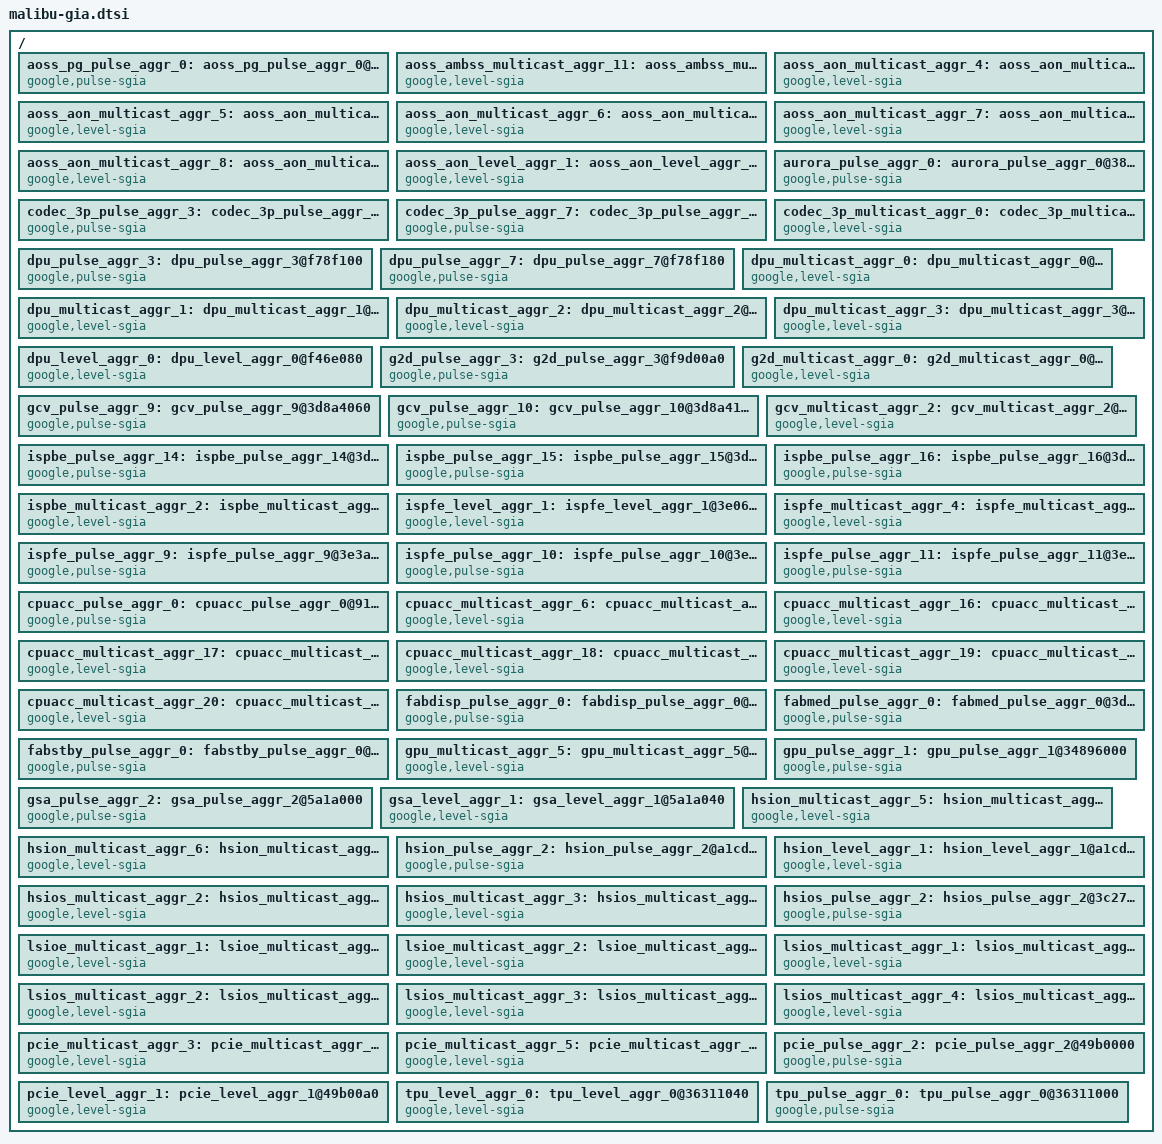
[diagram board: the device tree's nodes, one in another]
// SPDX-License-Identifier: GPL-2.0-only OR BSD-3-Clause
#include <dt-bindings/interrupt-controller/mbu-gic.h>
#include <dt-bindings/interrupt-controller/irq-gia-google-mbu.h>

/***** THIS FILE GENERATED USING gen-gia-device-tree.py *****/

/ {
	/* This node looks different because it is an N-N aggregator for aoss_pg_pulse_aggr_[0:6] */
	aoss_pg_pulse_aggr_0: aoss_pg_pulse_aggr_0@d856000 {
		compatible = "google,pulse-sgia";
		interrupt-controller;
		interrupt-parent = <&aoss_aon_multicast_aggr_8>;
		#interrupt-cells = <1>;
		reg = <0x0 0xd856000 0x0 0x20>;
		interrupts =
			<AOSS_GIA_MULTICAST_AGGR_8_AUX_PARTITION_INTR_PULSE_AGGR_INTR_0>,
			<AOSS_GIA_MULTICAST_AGGR_8_AUX_PARTITION_INTR_PULSE_AGGR_INTR_1>,
			<AOSS_GIA_MULTICAST_AGGR_8_AUX_PARTITION_INTR_PULSE_AGGR_INTR_2>,
			<AOSS_GIA_MULTICAST_AGGR_8_AUX_PARTITION_INTR_PULSE_AGGR_INTR_3>,
			<AOSS_GIA_MULTICAST_AGGR_8_AUX_PARTITION_INTR_PULSE_AGGR_INTR_4>,
			<AOSS_GIA_MULTICAST_AGGR_8_AUX_PARTITION_INTR_PULSE_AGGR_INTR_5>,
			<AOSS_GIA_MULTICAST_AGGR_8_AUX_PARTITION_INTR_PULSE_AGGR_INTR_6>;
	};

	aoss_ambss_multicast_aggr_11: aoss_ambss_multicast_aggr_11@d105000 {
		compatible = "google,level-sgia";
		interrupt-controller;
		#interrupt-cells = <1>;
		reg = <0x0 0xd105000 0x0 0x20>;
		interrupts = <GIC_SPI SSWRP_AOSS_AOSS_AP_INTR_NS_AOSSAMBSS_0 IRQ_TYPE_LEVEL_HIGH 0>;
	};

	aoss_aon_multicast_aggr_4: aoss_aon_multicast_aggr_4@e602020 {
		compatible = "google,level-sgia";
		interrupt-controller;
		interrupt-parent = <&aoss_aon_level_aggr_1>;
		#interrupt-cells = <1>;
		reg = <0x0 0xe602020 0x0 0x20>;
		interrupts = <AOSS_GIA_LEVEL_AGGR_1_AUX_AON_AON_PARTITION_AON_GIA_GIA_MULTICAST_AGGR_INTR_4>;
	};

	aoss_aon_multicast_aggr_5: aoss_aon_multicast_aggr_5@e602040 {
		compatible = "google,level-sgia";
		interrupt-controller;
		interrupt-parent = <&aoss_aon_level_aggr_1>;
		#interrupt-cells = <1>;
		reg = <0x0 0xe602040 0x0 0x20>;
		interrupts = <AOSS_GIA_LEVEL_AGGR_1_AUX_AON_AON_PARTITION_AON_GIA_GIA_MULTICAST_AGGR_INTR_5>;
	};

	aoss_aon_multicast_aggr_6: aoss_aon_multicast_aggr_6@e602060 {
		compatible = "google,level-sgia";
		interrupt-controller;
		interrupt-parent = <&aoss_aon_level_aggr_1>;
		#interrupt-cells = <1>;
		reg = <0x0 0xe602060 0x0 0x20>;
		interrupts = <AOSS_GIA_LEVEL_AGGR_1_AUX_AON_AON_PARTITION_AON_GIA_GIA_MULTICAST_AGGR_INTR_6>;
	};

	aoss_aon_multicast_aggr_7: aoss_aon_multicast_aggr_7@e602080 {
		compatible = "google,level-sgia";
		interrupt-controller;
		interrupt-parent = <&aoss_aon_level_aggr_1>;
		#interrupt-cells = <1>;
		reg = <0x0 0xe602080 0x0 0x20>;
		interrupts = <AOSS_GIA_LEVEL_AGGR_1_AUX_AON_AON_PARTITION_AON_GIA_GIA_MULTICAST_AGGR_INTR_7>;
	};

	aoss_aon_multicast_aggr_8: aoss_aon_multicast_aggr_8@e6020a0 {
		compatible = "google,level-sgia";
		interrupt-controller;
		interrupt-parent = <&aoss_aon_level_aggr_1>;
		#interrupt-cells = <1>;
		reg = <0x0 0xe6020a0 0x0 0x20>;
		interrupts = <AOSS_GIA_LEVEL_AGGR_1_AUX_AON_AON_PARTITION_AON_GIA_GIA_MULTICAST_AGGR_INTR_8>;
	};

	aoss_aon_level_aggr_1: aoss_aon_level_aggr_1@e6020c0 {
		compatible = "google,level-sgia";
		interrupt-controller;
		#interrupt-cells = <1>;
		reg = <0x0 0xe6020c0 0x0 0x20>;
		interrupts = <GIC_SPI SSWRP_AOSS_AOSS_GIA_OUT_AP_NS_0 IRQ_TYPE_LEVEL_HIGH 0>;
	};

	aurora_pulse_aggr_0: aurora_pulse_aggr_0@38061000 {
		compatible = "google,pulse-sgia";
		interrupt-controller;
		#interrupt-cells = <1>;
		reg = <0x0 0x38061000 0x0 0x20>;
		interrupts = <GIC_SPI SSWRP_AURORA_AURDSP_GIA_OUT_AP_NS_0 IRQ_TYPE_LEVEL_HIGH 0>;
		power-domains = <&sswrp_aurdsp_pd>;
	};

	codec_3p_pulse_aggr_3: codec_3p_pulse_aggr_3@3da700c0 {
		compatible = "google,pulse-sgia";
		interrupt-controller;
		interrupt-parent = <&codec_3p_multicast_aggr_0>;
		#interrupt-cells = <1>;
		reg = <0x0 0x3da700c0 0x0 0x20>;
		interrupts = <CODEC_3P_GIA_MULTICAST_AGGR_0_AUX_AON_DUMMY_GIA_LEAF_WRAPPER_PULSE_AGGR_INTR_3>;
		power-domains = <&sswrp_codec_3p_pd>;
	};

	codec_3p_pulse_aggr_7: codec_3p_pulse_aggr_7@3da700e0 {
		compatible = "google,pulse-sgia";
		interrupt-controller;
		interrupt-parent = <&codec_3p_multicast_aggr_0>;
		#interrupt-cells = <1>;
		reg = <0x0 0x3da700e0 0x0 0x20>;
		interrupts = <CODEC_3P_GIA_MULTICAST_AGGR_0_AUX_AON_DUMMY_GIA_LEAF_WRAPPER_PULSE_AGGR_INTR_7>;
		power-domains = <&sswrp_codec_3p_pd>;
	};

	codec_3p_multicast_aggr_0: codec_3p_multicast_aggr_0@3da6a000 {
		compatible = "google,level-sgia";
		interrupt-controller;
		#interrupt-cells = <1>;
		reg = <0x0 0x3da6a000 0x0 0x20>;
		interrupts = <GIC_SPI SSWRP_CODEC_3P_CODEC3P_GIA_OUT_AP_NS IRQ_TYPE_LEVEL_HIGH 0>;
		power-domains = <&sswrp_codec_3p_pd>;
	};

	dpu_pulse_aggr_3: dpu_pulse_aggr_3@f78f100 {
		compatible = "google,pulse-sgia";
		interrupt-controller;
		interrupt-parent = <&dpu_multicast_aggr_2>;
		#interrupt-cells = <1>;
		reg = <0x0 0xf78f100 0x0 0x20>;
		interrupts = <DPU_GIA_MULTICAST_AGGR_2_AUX_CORE_IRQ_DUMMY_GIA_LEAF_WRAPPER_PULSE_AGGR_INTR_3>;
		power-domains = <&sswrp_dpu_pd>;
	};

	dpu_pulse_aggr_7: dpu_pulse_aggr_7@f78f180 {
		compatible = "google,pulse-sgia";
		interrupt-controller;
		interrupt-parent = <&dpu_multicast_aggr_3>;
		#interrupt-cells = <1>;
		reg = <0x0 0xf78f180 0x0 0x20>;
		interrupts = <DPU_GIA_MULTICAST_AGGR_3_AUX_CORE_IRQ_DUMMY_GIA_LEAF_WRAPPER_PULSE_AGGR_INTR_7>;
		power-domains = <&sswrp_dpu_pd>;
	};

	dpu_multicast_aggr_0: dpu_multicast_aggr_0@f46e000 {
		compatible = "google,level-sgia";
		interrupt-controller;
		interrupt-parent = <&dpu_level_aggr_0>;
		#interrupt-cells = <1>;
		reg = <0x0 0xf46e000 0x0 0x20>;
		interrupts = <DPU_GIA_LEVEL_AGGR_0_AUX_AON_GIA_GIA_GIA_MULTICAST_AGGR_INTR_0>;
		power-domains = <&sswrp_dpu_pd>;
	};

	dpu_multicast_aggr_1: dpu_multicast_aggr_1@f46e020 {
		compatible = "google,level-sgia";
		interrupt-controller;
		interrupt-parent = <&dpu_level_aggr_0>;
		#interrupt-cells = <1>;
		reg = <0x0 0xf46e020 0x0 0x20>;
		interrupts = <DPU_GIA_LEVEL_AGGR_0_AUX_AON_GIA_GIA_GIA_MULTICAST_AGGR_INTR_1>;
		power-domains = <&sswrp_dpu_pd>;
	};

	dpu_multicast_aggr_2: dpu_multicast_aggr_2@f46e040 {
		compatible = "google,level-sgia";
		interrupt-controller;
		interrupt-parent = <&dpu_level_aggr_0>;
		#interrupt-cells = <1>;
		reg = <0x0 0xf46e040 0x0 0x20>;
		interrupts = <DPU_GIA_LEVEL_AGGR_0_AUX_AON_GIA_GIA_GIA_MULTICAST_AGGR_INTR_2>;
		power-domains = <&sswrp_dpu_pd>;
	};

	dpu_multicast_aggr_3: dpu_multicast_aggr_3@f46e060 {
		compatible = "google,level-sgia";
		interrupt-controller;
		interrupt-parent = <&dpu_level_aggr_0>;
		#interrupt-cells = <1>;
		reg = <0x0 0xf46e060 0x0 0x20>;
		interrupts = <DPU_GIA_LEVEL_AGGR_0_AUX_AON_GIA_GIA_GIA_MULTICAST_AGGR_INTR_3>;
		power-domains = <&sswrp_dpu_pd>;
	};

	dpu_level_aggr_0: dpu_level_aggr_0@f46e080 {
		compatible = "google,level-sgia";
		interrupt-controller;
		#interrupt-cells = <1>;
		reg = <0x0 0xf46e080 0x0 0x20>;
		interrupts = <GIC_SPI SSWRP_DPU_DPU_GIA_OUT_AP_NS IRQ_TYPE_LEVEL_HIGH 0>;
		power-domains = <&sswrp_dpu_pd>;
	};

	g2d_pulse_aggr_3: g2d_pulse_aggr_3@f9d00a0 {
		compatible = "google,pulse-sgia";
		interrupt-controller;
		interrupt-parent = <&g2d_multicast_aggr_0>;
		#interrupt-cells = <1>;
		reg = <0x0 0xf9d00a0 0x0 0x20>;
		interrupts = <G2D_GIA_MULTICAST_AGGR_0_AUX_CORE_IRQ_DUMMY_GIA_LEAF_WRAPPER_PULSE_AGGR_INTR_3>;
		power-domains = <&sswrp_g2d_pd>;
	};

	g2d_multicast_aggr_0: g2d_multicast_aggr_0@f822000 {
		compatible = "google,level-sgia";
		interrupt-controller;
		#interrupt-cells = <1>;
		reg = <0x0 0xf822000 0x0 0x20>;
		interrupts = <GIC_SPI SSWRP_G2D_G2D_GIA_OUT_AP_NS IRQ_TYPE_LEVEL_HIGH 0>;
		power-domains = <&sswrp_g2d_pd>;
	};

	gcv_pulse_aggr_9: gcv_pulse_aggr_9@3d8a4060 {
		compatible = "google,pulse-sgia";
		interrupt-controller;
		interrupt-parent = <&gcv_multicast_aggr_2>;
		#interrupt-cells = <1>;
		reg = <0x0 0x3d8a4060 0x0 0x20>;
		interrupts = <GCV_GIA_MULTICAST_AGGR_2_AUX_PD_AUX_QCHWRAP_DUMMY_GIA_LEAF_WRAPPER_PULSE_AGGR_INTR_9>;
		power-domains = <&sswrp_gcv_pd>;
	};

	gcv_pulse_aggr_10: gcv_pulse_aggr_10@3d8a4160 {
		compatible = "google,pulse-sgia";
		interrupt-controller;
		interrupt-parent = <&gcv_multicast_aggr_2>;
		#interrupt-cells = <1>;
		reg = <0x0 0x3d8a4160 0x0 0x20>;
		interrupts = <GCV_GIA_MULTICAST_AGGR_2_AUX_PD_AUX_QCHWRAP_DUMMY_GIA_LEAF_WRAPPER_PULSE_AGGR_INTR_10>;
		power-domains = <&sswrp_gcv_pd>;
	};

	gcv_multicast_aggr_2: gcv_multicast_aggr_2@3d812000 {
		compatible = "google,level-sgia";
		interrupt-controller;
		#interrupt-cells = <1>;
		reg = <0x0 0x3d812000 0x0 0x20>;
		interrupts = <GIC_SPI SSWRP_GCV_GCV_GIA_OUT_AP_NS IRQ_TYPE_LEVEL_HIGH 0>;
		power-domains = <&sswrp_gcv_pd>;
	};

	ispbe_pulse_aggr_14: ispbe_pulse_aggr_14@3d637060 {
		compatible = "google,pulse-sgia";
		interrupt-controller;
		interrupt-parent = <&ispbe_multicast_aggr_2>;
		#interrupt-cells = <1>;
		reg = <0x0 0x3d637060 0x0 0x20>;
		interrupts = <ISPBE_GIA_MULTICAST_AGGR_2_AUX_PD_AUX_QCHWRAP_DUMMY_GIA_LEAF_WRAPPER_PULSE_AGGR_INTR_14>;
		power-domains = <&sswrp_ispbe_pd>;
	};

	ispbe_pulse_aggr_15: ispbe_pulse_aggr_15@3d637160 {
		compatible = "google,pulse-sgia";
		interrupt-controller;
		interrupt-parent = <&ispbe_multicast_aggr_2>;
		#interrupt-cells = <1>;
		reg = <0x0 0x3d637160 0x0 0x20>;
		interrupts = <ISPBE_GIA_MULTICAST_AGGR_2_AUX_PD_AUX_QCHWRAP_DUMMY_GIA_LEAF_WRAPPER_PULSE_AGGR_INTR_15>;
		power-domains = <&sswrp_ispbe_pd>;
	};

	ispbe_pulse_aggr_16: ispbe_pulse_aggr_16@3d637260 {
		compatible = "google,pulse-sgia";
		interrupt-controller;
		interrupt-parent = <&ispbe_multicast_aggr_2>;
		#interrupt-cells = <1>;
		reg = <0x0 0x3d637260 0x0 0x20>;
		interrupts = <ISPBE_GIA_MULTICAST_AGGR_2_AUX_PD_AUX_QCHWRAP_DUMMY_GIA_LEAF_WRAPPER_PULSE_AGGR_INTR_16>;
		power-domains = <&sswrp_ispbe_pd>;
	};

	ispbe_multicast_aggr_2: ispbe_multicast_aggr_2@3d412000 {
		compatible = "google,level-sgia";
		interrupt-controller;
		#interrupt-cells = <1>;
		reg = <0x0 0x3d412000 0x0 0x20>;
		interrupts = <GIC_SPI SSWRP_ISPBE_ISPBE_GIA_OUT_AP_NS IRQ_TYPE_LEVEL_HIGH 0>;
		power-domains = <&sswrp_ispbe_pd>;
	};

	ispfe_level_aggr_1: ispfe_level_aggr_1@3e063040 {
		compatible = "google,level-sgia";
		interrupt-controller;
		#interrupt-cells = <1>;
		reg = <0x0 0x3e063040 0x0 0x20>;
		interrupts = <GIC_SPI SSWRP_ISPFE_ISPFE_GIA_OUT_AP_NS IRQ_TYPE_LEVEL_HIGH 0>;
		power-domains = <&sswrp_ispfe_pd>;
	};

	ispfe_multicast_aggr_4: ispfe_multicast_aggr_4@3e063000 {
		compatible = "google,level-sgia";
		interrupt-controller;
		interrupt-parent = <&ispfe_level_aggr_1>;
		#interrupt-cells = <1>;
		reg = <0x0 0x3e063000 0x0 0x20>;
		interrupts = <ISPFE_GIA_LEVEL_AGGR_1_AUX_AON_AON_GIA_MULTICAST_AGGR_INTR_4>;
		power-domains = <&sswrp_ispfe_pd>;
	};

	ispfe_pulse_aggr_9: ispfe_pulse_aggr_9@3e3a0120 {
		compatible = "google,pulse-sgia";
		interrupt-controller;
		interrupt-parent = <&ispfe_multicast_aggr_4>;
		#interrupt-cells = <1>;
		reg = <0x0 0x3e3a0120 0x0 0x20>;
		interrupts = <ISPFE_GIA_MULTICAST_AGGR_4_AUX_DUMMY_GIA_LEAF_WRAPPER_PULSE_AGGR_INTR_9>;
		power-domains = <&sswrp_ispfe_pd>;
	};

	ispfe_pulse_aggr_10: ispfe_pulse_aggr_10@3e3a0140 {
		compatible = "google,pulse-sgia";
		interrupt-controller;
		interrupt-parent = <&ispfe_multicast_aggr_4>;
		#interrupt-cells = <1>;
		reg = <0x0 0x3e3a0140 0x0 0x20>;
		interrupts = <ISPFE_GIA_MULTICAST_AGGR_4_AUX_DUMMY_GIA_LEAF_WRAPPER_PULSE_AGGR_INTR_10>;
		power-domains = <&sswrp_ispfe_pd>;
	};

	ispfe_pulse_aggr_11: ispfe_pulse_aggr_11@3e3a0160 {
		compatible = "google,pulse-sgia";
		interrupt-controller;
		interrupt-parent = <&ispfe_multicast_aggr_4>;
		#interrupt-cells = <1>;
		reg = <0x0 0x3e3a0160 0x0 0x20>;
		interrupts = <ISPFE_GIA_MULTICAST_AGGR_4_AUX_DUMMY_GIA_LEAF_WRAPPER_PULSE_AGGR_INTR_11>;
		power-domains = <&sswrp_ispfe_pd>;
	};

	cpuacc_pulse_aggr_0: cpuacc_pulse_aggr_0@91c2000 {
		compatible = "google,pulse-sgia";
		interrupt-controller;
		#interrupt-cells = <1>;
		reg = <0x0 0x91c2000 0x0 0x20>;
		interrupts = <GIC_SPI SSWRP_CPUACC_CPUACC_GIA_OUT_AP_NS_0 IRQ_TYPE_LEVEL_HIGH 0>;
	};

	cpuacc_multicast_aggr_6: cpuacc_multicast_aggr_6@91c2020 {
		compatible = "google,level-sgia";
		interrupt-controller;
		#interrupt-cells = <1>;
		reg = <0x0 0x91c2020 0x0 0x20>;
		interrupts = <GIC_SPI SSWRP_CPUACC_CPUACC_GIA_OUT_AP_NS_1 IRQ_TYPE_LEVEL_HIGH 0>;
	};

	cpuacc_multicast_aggr_16: cpuacc_multicast_aggr_16@91c6000 {
		compatible = "google,level-sgia";
		interrupt-controller;
		#interrupt-cells = <1>;
		reg = <0x0 0x91c6000 0x0 0x20>;
		interrupts = <GIC_SPI SSWRP_CPUACC_CPUACC_GIA_OUT_AP_0_0 IRQ_TYPE_LEVEL_HIGH 0>;
	};

	cpuacc_multicast_aggr_17: cpuacc_multicast_aggr_17@91c7000 {
		compatible = "google,level-sgia";
		interrupt-controller;
		#interrupt-cells = <1>;
		reg = <0x0 0x91c7000 0x0 0x20>;
		interrupts = <GIC_SPI SSWRP_CPUACC_CPUACC_GIA_OUT_AP_0_1 IRQ_TYPE_LEVEL_HIGH 0>;
	};

	cpuacc_multicast_aggr_18: cpuacc_multicast_aggr_18@91c8000 {
		compatible = "google,level-sgia";
		interrupt-controller;
		#interrupt-cells = <1>;
		reg = <0x0 0x91c8000 0x0 0x20>;
		interrupts = <GIC_SPI SSWRP_CPUACC_CPUACC_GIA_OUT_AP_0_2 IRQ_TYPE_LEVEL_HIGH 0>;
	};

	cpuacc_multicast_aggr_19: cpuacc_multicast_aggr_19@91c9000 {
		compatible = "google,level-sgia";
		interrupt-controller;
		#interrupt-cells = <1>;
		reg = <0x0 0x91c9000 0x0 0x20>;
		interrupts = <GIC_SPI SSWRP_CPUACC_CPUACC_GIA_OUT_AP_0_3 IRQ_TYPE_LEVEL_HIGH 0>;
	};

	cpuacc_multicast_aggr_20: cpuacc_multicast_aggr_20@91ca000 {
		compatible = "google,level-sgia";
		interrupt-controller;
		#interrupt-cells = <1>;
		reg = <0x0 0x91ca000 0x0 0x20>;
		interrupts = <GIC_SPI SSWRP_CPUACC_CPUACC_GIA_OUT_AP_0_4 IRQ_TYPE_LEVEL_HIGH 0>;
	};

	fabdisp_pulse_aggr_0: fabdisp_pulse_aggr_0@f371000 {
		compatible = "google,pulse-sgia";
		interrupt-controller;
		#interrupt-cells = <1>;
		reg = <0x0 0xf371000 0x0 0x20>;
		interrupts = <GIC_SPI SSWRP_FABDISP_FABDISP_GIA_OUT_AP_NS_0 IRQ_TYPE_LEVEL_HIGH 0>;
	};

	fabmed_pulse_aggr_0: fabmed_pulse_aggr_0@3d371000 {
		compatible = "google,pulse-sgia";
		interrupt-controller;
		#interrupt-cells = <1>;
		reg = <0x0 0x3d371000 0x0 0x20>;
		interrupts = <GIC_SPI SSWRP_FABMED_FABMED_GIA_OUT_AP_NS_0 IRQ_TYPE_LEVEL_HIGH 0>;
	};

	fabstby_pulse_aggr_0: fabstby_pulse_aggr_0@4371000 {
		compatible = "google,pulse-sgia";
		interrupt-controller;
		#interrupt-cells = <1>;
		reg = <0x0 0x4371000 0x0 0x20>;
		interrupts = <GIC_SPI SSWRP_FABSTBY_FABSTBY_GIA_OUT_AP_NS_0 IRQ_TYPE_LEVEL_HIGH 0>;
	};

	gpu_multicast_aggr_5: gpu_multicast_aggr_5@34896020 {
		compatible = "google,level-sgia";
		interrupt-controller;
		#interrupt-cells = <1>;
		reg = <0x0 0x34896020 0x0 0x20>;
		interrupts = <GIC_SPI SSWRP_GPU_GPU_GIA_OUT_AP_NS IRQ_TYPE_LEVEL_HIGH 0>;
		power-domains = <&sswrp_gpu_pd>;
	};

	gpu_pulse_aggr_1: gpu_pulse_aggr_1@34896000 {
		compatible = "google,pulse-sgia";
		interrupt-controller;
		interrupt-parent = <&gpu_multicast_aggr_5>;
		#interrupt-cells = <1>;
		reg = <0x0 0x34896000 0x0 0x20>;
		interrupts = <GPU_GIA_MULTICAST_AGGR_5_AUX_AON_AON_GIA_PULSE_AGGR_INTR_1>;
		power-domains = <&sswrp_gpu_pd>;
	};

	gsa_pulse_aggr_2: gsa_pulse_aggr_2@5a1a000 {
		compatible = "google,pulse-sgia";
		interrupt-controller;
		interrupt-parent = <&gsa_level_aggr_1>;
		#interrupt-cells = <1>;
		reg = <0x0 0x5a1a000 0x0 0x20>;
		interrupts = <GSA_GIA_LEVEL_AGGR_1_AUX_AON_AON_GIA_GIA_PULSE_AGGR_INTR_2>;
	};

	gsa_level_aggr_1: gsa_level_aggr_1@5a1a040 {
		compatible = "google,level-sgia";
		interrupt-controller;
		#interrupt-cells = <1>;
		reg = <0x0 0x5a1a040 0x0 0x20>;
		interrupts = <GIC_SPI SSWRP_GSA_GSA_GIA_OUT_AP_NS IRQ_TYPE_LEVEL_HIGH 0>;
	};

	hsion_multicast_aggr_5: hsion_multicast_aggr_5@a1cd060 {
		compatible = "google,level-sgia";
		interrupt-controller;
		#interrupt-cells = <1>;
		reg = <0x0 0xa1cd060 0x0 0x20>;
		interrupts = <GIC_SPI SSWRP_HSIO_N_HSION_GIA_OUT_AP_NS_1 IRQ_TYPE_LEVEL_HIGH 0>;
		power-domains = <&sswrp_hsio_n_pd>;
	};

	hsion_multicast_aggr_6: hsion_multicast_aggr_6@a1cd080 {
		compatible = "google,level-sgia";
		interrupt-controller;
		#interrupt-cells = <1>;
		reg = <0x0 0xa1cd080 0x0 0x20>;
		interrupts = <GIC_SPI SSWRP_HSIO_N_HSION_GIA_OUT_AP_NS_2 IRQ_TYPE_LEVEL_HIGH 0>;
		power-domains = <&sswrp_hsio_n_pd>;
	};

	hsion_pulse_aggr_2: hsion_pulse_aggr_2@a1cd000 {
		compatible = "google,pulse-sgia";
		interrupt-controller;
		interrupt-parent = <&hsion_level_aggr_1>;
		#interrupt-cells = <1>;
		reg = <0x0 0xa1cd000 0x0 0x20>;
		interrupts = <HSION_GIA_LEVEL_AGGR_1_HSIO_N_AUX_HSIO_N_HSIO_N_GIA_PULSE_AGGR_INTR_2>;
		power-domains = <&sswrp_hsio_n_pd>;
	};

	hsion_level_aggr_1: hsion_level_aggr_1@a1cd0a0 {
		compatible = "google,level-sgia";
		interrupt-controller;
		#interrupt-cells = <1>;
		reg = <0x0 0xa1cd0a0 0x0 0x20>;
		interrupts = <GIC_SPI SSWRP_HSIO_N_HSION_GIA_OUT_AP_NS_3 IRQ_TYPE_LEVEL_HIGH 0>;
		power-domains = <&sswrp_hsio_n_pd>;
	};

	hsios_multicast_aggr_2: hsios_multicast_aggr_2@3c272040 {
		compatible = "google,level-sgia";
		interrupt-controller;
		#interrupt-cells = <1>;
		reg = <0x0 0x3c272040 0x0 0x20>;
		interrupts = <GIC_SPI SSWRP_HSIO_S_HSIOS_GIA_OUT_AP_NS_2 IRQ_TYPE_LEVEL_HIGH 0>;
		power-domains = <&sswrp_hsio_s_pd>;
	};

	hsios_multicast_aggr_3: hsios_multicast_aggr_3@3c272060 {
		compatible = "google,level-sgia";
		interrupt-controller;
		#interrupt-cells = <1>;
		reg = <0x0 0x3c272060 0x0 0x20>;
		interrupts = <GIC_SPI SSWRP_HSIO_S_HSIOS_GIA_OUT_AP_NS_3 IRQ_TYPE_LEVEL_HIGH 0>;
		power-domains = <&sswrp_hsio_s_pd>;
	};

	hsios_pulse_aggr_2: hsios_pulse_aggr_2@3c272000 {
		compatible = "google,pulse-sgia";
		interrupt-controller;
		#interrupt-cells = <1>;
		reg = <0x0 0x3c272000 0x0 0x20>;
		interrupts = <GIC_SPI SSWRP_HSIO_S_HSIOS_GIA_OUT_AP_NS_0 IRQ_TYPE_LEVEL_HIGH 0>;
		power-domains = <&sswrp_hsio_s_pd>;
	};

	lsioe_multicast_aggr_1: lsioe_multicast_aggr_1@3a0d2020 {
		compatible = "google,level-sgia";
		interrupt-controller;
		#interrupt-cells = <1>;
		reg = <0x0 0x3a0d2020 0x0 0x20>;
		interrupts = <GIC_SPI SSWRP_LSIOE_LSIOE_GIA_OUT_AP_NS_1 IRQ_TYPE_LEVEL_HIGH 0>;
		power-domains = <&sswrp_lsio_e_pd>;
	};

	lsioe_multicast_aggr_2: lsioe_multicast_aggr_2@3a0d2040 {
		compatible = "google,level-sgia";
		interrupt-controller;
		#interrupt-cells = <1>;
		reg = <0x0 0x3a0d2040 0x0 0x20>;
		interrupts = <GIC_SPI SSWRP_LSIOE_LSIOE_GIA_OUT_AP_NS_2 IRQ_TYPE_LEVEL_HIGH 0>;
		power-domains = <&sswrp_lsio_e_pd>;
	};

	lsios_multicast_aggr_1: lsios_multicast_aggr_1@3bcd2020 {
		compatible = "google,level-sgia";
		interrupt-controller;
		#interrupt-cells = <1>;
		reg = <0x0 0x3bcd2020 0x0 0x20>;
		interrupts = <GIC_SPI SSWRP_LSIOS_LSIOS_GIA_OUT_AP_NS_1 IRQ_TYPE_LEVEL_HIGH 0>;
		power-domains = <&sswrp_lsio_s_pd>;
	};

	lsios_multicast_aggr_2: lsios_multicast_aggr_2@3bcd2040 {
		compatible = "google,level-sgia";
		interrupt-controller;
		#interrupt-cells = <1>;
		reg = <0x0 0x3bcd2040 0x0 0x20>;
		interrupts = <GIC_SPI SSWRP_LSIOS_LSIOS_GIA_OUT_AP_NS_2 IRQ_TYPE_LEVEL_HIGH 0>;
		power-domains = <&sswrp_lsio_s_pd>;
	};

	lsios_multicast_aggr_3: lsios_multicast_aggr_3@3bcd2060 {
		compatible = "google,level-sgia";
		interrupt-controller;
		#interrupt-cells = <1>;
		reg = <0x0 0x3bcd2060 0x0 0x20>;
		interrupts = <GIC_SPI SSWRP_LSIOS_LSIOS_GIA_OUT_AP_NS_3 IRQ_TYPE_LEVEL_HIGH 0>;
		power-domains = <&sswrp_lsio_s_pd>;
	};

	lsios_multicast_aggr_4: lsios_multicast_aggr_4@3bcd2080 {
		compatible = "google,level-sgia";
		interrupt-controller;
		#interrupt-cells = <1>;
		reg = <0x0 0x3bcd2080 0x0 0x20>;
		interrupts = <GIC_SPI SSWRP_LSIOS_LSIOS_GIA_OUT_AP_NS_4 IRQ_TYPE_LEVEL_HIGH 0>;
		power-domains = <&sswrp_lsio_s_pd>;
	};

	pcie_multicast_aggr_3: pcie_multicast_aggr_3@49b0040 {
		compatible = "google,level-sgia";
		interrupt-controller;
		interrupt-parent = <&pcie_level_aggr_1>;
		#interrupt-cells = <1>;
		reg = <0x0 0x49b0040 0x0 0x20>;
		interrupts = <PCIE_GIA_LEVEL_AGGR_1_AUX_GIA_MULTICAST_AGGR_INTR_3>;
		power-domains = <&sswrp_pcie_pd>;
	};

	pcie_multicast_aggr_5: pcie_multicast_aggr_5@49b0080 {
		compatible = "google,level-sgia";
		interrupt-controller;
		interrupt-parent = <&pcie_level_aggr_1>;
		#interrupt-cells = <1>;
		reg = <0x0 0x49b0080 0x0 0x20>;
		interrupts = <PCIE_GIA_LEVEL_AGGR_1_AUX_GIA_MULTICAST_AGGR_INTR_5>;
		power-domains = <&sswrp_pcie_pd>;
	};

	pcie_pulse_aggr_2: pcie_pulse_aggr_2@49b0000 {
		compatible = "google,pulse-sgia";
		interrupt-controller;
		interrupt-parent = <&pcie_level_aggr_1>;
		#interrupt-cells = <1>;
		reg = <0x0 0x49b0000 0x0 0x20>;
		interrupts = <PCIE_GIA_LEVEL_AGGR_1_AUX_GIA_PULSE_AGGR_INTR_2>;
		power-domains = <&sswrp_pcie_pd>;
	};

	pcie_level_aggr_1: pcie_level_aggr_1@49b00a0 {
		compatible = "google,level-sgia";
		interrupt-controller;
		#interrupt-cells = <1>;
		reg = <0x0 0x49b00a0 0x0 0x20>;
		interrupts = <GIC_SPI SSWRP_PCIE_PCIE_GIA_OUT_AP_NS IRQ_TYPE_LEVEL_HIGH 0>;
		power-domains = <&sswrp_pcie_pd>;
	};

	tpu_level_aggr_0: tpu_level_aggr_0@36311040 {
		compatible = "google,level-sgia";
		interrupt-controller;
		#interrupt-cells = <1>;
		reg = <0x0 0x36311040 0x0 0x20>;
		interrupts = <GIC_SPI SSWRP_TPU_TPU_GIA_OUT_AP_NS_GRP0 IRQ_TYPE_LEVEL_HIGH 0>;
		power-domains = <&sswrp_tpu_pd>;
	};

	tpu_pulse_aggr_0: tpu_pulse_aggr_0@36311000 {
		compatible = "google,pulse-sgia";
		interrupt-controller;
		interrupt-parent = <&tpu_level_aggr_0>;
		#interrupt-cells = <1>;
		reg = <0x0 0x36311000 0x0 0x20>;
		interrupts = <TPU_GIA_LEVEL_AGGR_0_AUX_AON_GIA_PULSE_AGGR_INTR_0>;
		power-domains = <&sswrp_tpu_pd>;
	};
};
